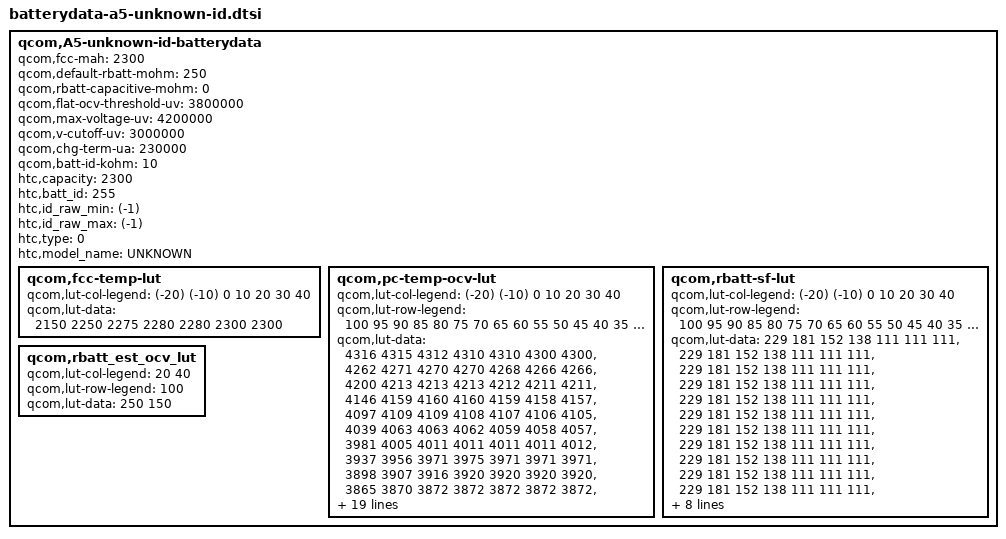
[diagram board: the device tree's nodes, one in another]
qcom,A5-unknown-id-batterydata {
	qcom,fcc-mah = <2300>;
	qcom,default-rbatt-mohm = <250>;
	qcom,rbatt-capacitive-mohm = <0>;
	qcom,flat-ocv-threshold-uv = <3800000>;
	qcom,max-voltage-uv = <4200000>;
	qcom,v-cutoff-uv = <3000000>;
	qcom,chg-term-ua = <230000>;
	qcom,batt-id-kohm = <10>;
	htc,capacity = <2300>;
	htc,batt_id = <255>;
	htc,id_raw_min = <(-1)>;
	htc,id_raw_max = <(-1)>;
	htc,type = <0>;
	htc,model_name = "UNKNOWN";

	qcom,fcc-temp-lut {
		qcom,lut-col-legend = <(-20) (-10) 0 10 20 30 40>;
		qcom,lut-data = <2150 2250 2275 2280 2280 2300 2300>;
	};

	qcom,pc-temp-ocv-lut {
		qcom,lut-col-legend = <(-20) (-10) 0 10 20 30 40>;
		qcom,lut-row-legend = <100 95 90 85 80 75 70 65 60 55 50 45 40 35 30 25 20 15 10 9 8 7 6 5 4 3 2 1 0>;
		qcom,lut-data = <4316 4315 4312 4310 4310 4300 4300>,
				<4262 4271 4270 4270 4268 4266 4266>,
				<4200 4213 4213 4213 4212 4211 4211>,
				<4146 4159 4160 4160 4159 4158 4157>,
				<4097 4109 4109 4108 4107 4106 4105>,
				<4039 4063 4063 4062 4059 4058 4057>,
				<3981 4005 4011 4011 4011 4011 4012>,
				<3937 3956 3971 3975 3971 3971 3971>,
				<3898 3907 3916 3920 3920 3920 3920>,
				<3865 3870 3872 3872 3872 3872 3872>,
				<3839 3842 3844 3844 3844 3844 3844>,
				<3819 3820 3822 3823 3823 3823 3823>,
				<3806 3805 3805 3805 3804 3804 3804>,
				<3793 3790 3790 3787 3784 3784 3784>,
				<3777 3777 3777 3777 3768 3768 3768>,
				<3757 3762 3762 3762 3749 3749 3749>,
				<3734 3728 3728 3725 3723 3723 3723>,
				<3715 3704 3703 3701 3701 3701 3701>,
				<3693 3693 3693 3691 3691 3691 3691>,
				<3682 3681 3681 3681 3681 3681 3681>,
				<3670 3669 3669 3669 3669 3669 3669>,
				<3655 3655 3655 3655 3655 3655 3655>,
				<3641 3640 3640 3640 3640 3640 3640>,
				<3618 3618 3618 3618 3618 3618 3618>,
				<3603 3558 3558 3556 3556 3556 3556>,
				<3588 3526 3494 3490 3490 3490 3490>,
				<3568 3496 3411 3407 3407 3407 3407>,
				<3535 3449 3297 3271 3271 3271 3271>,
				<3469 3355 3069 3000 3000 3000 3000>;
	};

	qcom,rbatt-sf-lut {
		qcom,lut-col-legend = <(-20) (-10) 0 10 20 30 40>;
		qcom,lut-row-legend = <100 95 90 85 80 75 70 65 60 55 50 45 40 35 30 25 20 15 10>;
		qcom,lut-data = <229 181 152 138 111 111 111>,
				<229 181 152 138 111 111 111>,
				<229 181 152 138 111 111 111>,
				<229 181 152 138 111 111 111>,
				<229 181 152 138 111 111 111>,
				<229 181 152 138 111 111 111>,
				<229 181 152 138 111 111 111>,
				<229 181 152 138 111 111 111>,
				<229 181 152 138 111 111 111>,
				<229 181 152 138 111 111 111>,
				<229 181 152 138 111 111 111>,
				<229 181 152 138 111 111 111>,
				<229 181 152 138 111 111 111>,
				<229 181 152 138 111 111 111>,
				<229 181 152 138 111 111 111>,
				<229 181 152 138 111 111 111>,
				<229 181 152 138 111 111 111>,
				<229 181 152 138 111 111 111>,
				<229 181 152 138 111 111 111>;
	};

	qcom,rbatt_est_ocv_lut {
		qcom,lut-col-legend = <20 40>;
		qcom,lut-row-legend = <100>;
		qcom,lut-data = <250 150>;
	};
};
